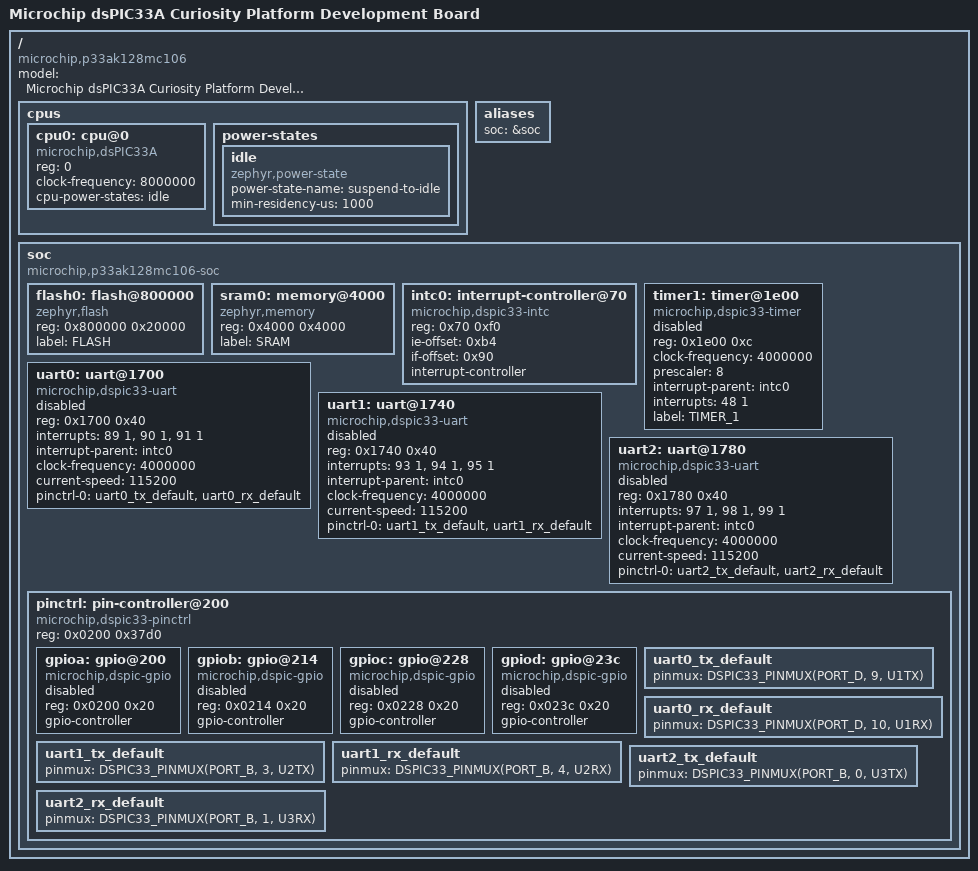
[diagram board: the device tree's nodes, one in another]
/*
 * Copyright (c) 2025, Microchip Technology Inc.
 * SPDX-License-Identifier: Apache-2.0
 */

#include "zephyr/dt-bindings/pinctrl/mchp-p33ak128mc106-pinctrl.h"

/ {
	model = "Microchip dsPIC33A Curiosity Platform Development Board";
	compatible = "microchip,p33ak128mc106";

	cpus {
		#address-cells = <1>;
		#size-cells = <0>;

		cpu0: cpu@0 {
			device_type = "cpu";
			compatible = "microchip,dsPIC33A";
			reg = <0>;
			clock-frequency = <8000000>;
			status = "okay";
			cpu-power-states = <&idle>;
		};

		power-states {
			idle: idle {
				compatible = "zephyr,power-state";
				power-state-name = "suspend-to-idle";
				min-residency-us = <1000>;
			};
		};
	};

	aliases {
		soc = &soc;
	};

	soc: soc {
		compatible = "microchip,p33ak128mc106-soc";
		#address-cells = <1>;
		#size-cells = <1>;

		flash0: flash@800000 {
			compatible = "zephyr,flash";
			reg = <0x800000 0x20000>;
			label = "FLASH";
		};

		sram0: memory@4000 {
			compatible = "zephyr,memory";
			reg = <0x4000 0x4000>;
			label = "SRAM";
		};

		intc0: interrupt-controller@70 {
			compatible = "microchip,dspic33-intc";
			reg = <0x70 0xf0>;
			ie-offset = <0xb4>;
			if-offset = <0x90>;
			interrupt-controller;
			#address-cells = <0>;
			#interrupt-cells = <2>;
		};

		timer1: timer@1e00 {
			compatible = "microchip,dspic33-timer";
			reg = <0x1e00 0xc>;
			clock-frequency = <4000000>;
			prescaler = <8>;
			interrupt-parent = <&intc0>;
			interrupts = <48 1>;
			label = "TIMER_1";
			status = "disabled";
		};

		uart0: uart@1700 {
			compatible = "microchip,dspic33-uart";
			reg = <0x1700 0x40>;
			interrupts = <89 1>, <90 1>, <91 1>;
			interrupt-names = "rx", "tx", "err";
			interrupt-parent = <&intc0>;
			clock-frequency = <4000000>;
			current-speed = <115200>;
			pinctrl-0 = <&uart0_tx_default &uart0_rx_default>;
			pinctrl-names = "default";
			status = "disabled";
		};

		uart1: uart@1740 {
			compatible = "microchip,dspic33-uart";
			reg = <0x1740 0x40>;
			interrupts = <93 1>, <94 1>, <95 1>;
			interrupt-names = "rx", "tx", "err";
			interrupt-parent = <&intc0>;
			clock-frequency = <4000000>;
			current-speed = <115200>;
			pinctrl-0 = <&uart1_tx_default &uart1_rx_default>;
			pinctrl-names = "default";
			status = "disabled";
		};

		uart2: uart@1780 {
			compatible = "microchip,dspic33-uart";
			reg = <0x1780 0x40>;
			interrupts = <97 1>, <98 1>, <99 1>;
			interrupt-names = "rx", "tx", "err";
			interrupt-parent = <&intc0>;
			clock-frequency = <4000000>;
			current-speed = <115200>;
			pinctrl-0 = <&uart2_tx_default &uart2_rx_default>;
			pinctrl-names = "default";
			status = "disabled";
		};

		pinctrl: pin-controller@200 {
			compatible = "microchip,dspic33-pinctrl";
			reg = <0x0200 0x37d0>;
			#address-cells = <1>;
			#size-cells = <1>;
			status = "okay";

			gpioa: gpio@200 {
				compatible = "microchip,dspic-gpio";
				reg = <0x0200 0x20>;
				gpio-controller;
				#gpio-cells = <2>;
				status = "disabled";
			};

			gpiob: gpio@214 {
				compatible = "microchip,dspic-gpio";
				reg = <0x0214 0x20>;
				gpio-controller;
				#gpio-cells = <2>;
				status = "disabled";
			};

			gpioc: gpio@228 {
				compatible = "microchip,dspic-gpio";
				reg = <0x0228 0x20>;
				gpio-controller;
				#gpio-cells = <2>;
				status = "disabled";
			};

			gpiod: gpio@23c {
				compatible = "microchip,dspic-gpio";
				reg = <0x023c 0x20>;
				gpio-controller;
				#gpio-cells = <2>;
				status = "disabled";
			};

			uart0_tx_default: uart0_tx_default {
				pinmux = <DSPIC33_PINMUX(PORT_D, 9, U1TX)>;
			};

			uart0_rx_default: uart0_rx_default {
				pinmux = <DSPIC33_PINMUX(PORT_D, 10, U1RX)>;
			};

			uart1_tx_default: uart1_tx_default {
				pinmux = <DSPIC33_PINMUX(PORT_B, 3, U2TX)>;
			};

			uart1_rx_default: uart1_rx_default {
				pinmux = <DSPIC33_PINMUX(PORT_B, 4, U2RX)>;
			};

			uart2_tx_default: uart2_tx_default {
				pinmux = <DSPIC33_PINMUX(PORT_B, 0, U3TX)>;
			};

			uart2_rx_default: uart2_rx_default {
				pinmux = <DSPIC33_PINMUX(PORT_B, 1, U3RX)>;
			};
		};
	};
};
